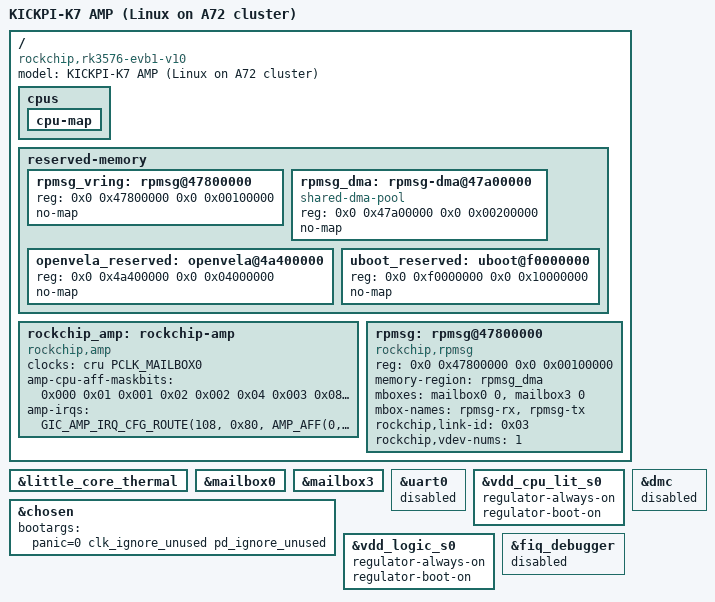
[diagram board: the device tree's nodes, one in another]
// SPDX-License-Identifier: (GPL-2.0+ OR MIT)
/*
 * KICKPI-K7 AMP：Linux 只占 A72 簇，A53 簇留给 openvela。
 *
 * 复制到 kernel-6.1/arch/arm64/boot/dts/rockchip/ 后编译。
 * 基线是 SDK 自带的 rk3576-kickpi-k7-linux.dts（K7 在 SDK 里是有板级
 * 支持的，不用拿 EVB 凑）。
 *
 * Copyright (c) 2026 contest2026_423_nanshannan
 */

/dts-v1/;

#include "rk3576.dtsi"
#include "rk3576-kickpi-k7.dtsi"
#include "rk3576-linux.dtsi"
#include <dt-bindings/soc/rockchip-amp.h>

/* MPIDR 的两段：低 8 位是簇内核号，高 8 位是簇号 */
#define AMP_AFF(core, cluster)	(((core) << 0) | ((cluster) << 8))

/ {
	model = "KICKPI-K7 AMP (Linux on A72 cluster)";
	compatible = "rockchip,rk3576-evb1-v10", "rockchip,rk3576";

	/*
	 * ★ A53 的四个 cpu 节点必须**删掉**，不能只标 status = "disabled"。
	 *
	 * 这版 vendor 内核枚举 CPU 时不看 status，标 disabled 它照样会去
	 * PSCI CPU_ON 那四个核 —— 而那四个核此刻正在跑 openvela。结果是
	 * 两个 OS 同时以为自己拥有同一颗核。
	 *
	 * 这一条来自同届 contest2026_062_PharosTech 的板测结论
	 * （其 tools/amp/TOPOLOGY.md），不是我们自己试出来的。
	 *
	 * 删 cpu 节点会留下悬空引用，所以 cpu-map 和 PMU 的 interrupt-affinity
	 * 也要一起改。
	 */

	cpus {
		/delete-node/ cpu@0;
		/delete-node/ cpu@1;
		/delete-node/ cpu@2;
		/delete-node/ cpu@3;

		cpu-map {
			/delete-node/ cluster0;
		};
	};

	/*
	 * 删掉 cpu_l* 会留下两处悬空的 phandle 引用。dtc 会直接报错，不会让
	 * 你带着它们编过去 —— 这一点恰恰比 status = "disabled" 好：后者编得过，
	 * 错误留到运行期才炸。
	 *
	 *   pmu-a53 的 interrupt-affinity → cpu_l0..l3
	 *   little-core-thermal 的 map0   → cpu_l0（A53 簇的调频降温，
	 *                                  这个簇的频率现在归 openvela）
	 */

	/delete-node/ pmu-a53;

	/*
	 * AMP 共享内存。这三段必须和 openvela 侧对上：
	 *   chip/rk3576/include/amp.h 的 RK3576_RPTUN_*
	 *   board/kickpi-k7/configs/amp/defconfig 的 CONFIG_RK3576_RPTUN_SHM_BASE
	 *
	 * no-map：不能让 Linux 把它当普通内存用。Rockchip 的 rpmsg 驱动对
	 * vring 用 ioremap()，对缓冲池用 shared-dma-pool，两者都要求这块
	 * 内存不在内核的线性映射里。
	 */

	reserved-memory {
		#address-cells = <2>;
		#size-cells = <2>;
		ranges;

		rpmsg_vring: rpmsg@47800000 {
			reg = <0x0 0x47800000 0x0 0x00100000>;
			no-map;
		};

		rpmsg_dma: rpmsg-dma@47a00000 {
			compatible = "shared-dma-pool";
			reg = <0x0 0x47a00000 0x0 0x00200000>;
			no-map;
		};

		/*
		 * openvela 自己那一块。Linux 完全不碰，只是占位，免得内核把它
		 * 分配出去。
		 *
		 * 起点 = openvela 的 CONFIG_RAM_START，长度 = CONFIG_RAM_SIZE
		 * （64MB）。这两个数必须和 board/kickpi-k7/configs/amp/defconfig
		 * 一致：写小了 Linux 会把 openvela 的堆当成自己的内存分出去，
		 * 表现是两边随机踩对方的数据，谁先崩不一定。
		 */

		openvela_reserved: openvela@4a400000 {
			reg = <0x0 0x4a400000 0x0 0x04000000>;
			no-map;
		};

		/*
		 * ★ U-Boot 自己占的那一段，也必须保留。
		 *
		 *   AMP 里 U-Boot 在 PSCI 拉起 Linux **之后**还要继续跑几毫秒：
		 *   处理 loadables、flush_dcache_all、最后才 armv8_switch_to_el2
		 *   跳进 openvela。而它重定位后位于高位内存（本板
		 *   0x40200000 + reloc_off ≈ 0xfdc1b000，栈和 malloc 在其下方）。
		 *
		 *   Linux 的 /memory 覆盖这一段。它的页分配器一旦工作，就可能把
		 *   U-Boot 正在执行的代码或它的栈分配出去 —— 表现是 **CPU0 在
		 *   任意一行上静默死掉，而 Linux 一切正常**，看起来像"openvela
		 *   没被启动"。
		 *
		 *   这一条上板踩过：Linux 拿错 FDT 秒死的那几轮，CPU0 反而能顺利
		 *   跳进 openvela；等 Linux 真的跑起来，CPU0 就再也走不到那一步。
		 *   两个现象合在一起才指向这里。
		 *
		 *   ★ 范围不能按 relocaddr 往上算 —— 第一次就是这么错的。
		 *
		 *   日志里 `Relocation Offset: bda1b000` + TEXT_BASE 0x40200000
		 *   = 0xfdc1b000，看起来从 0xfd000000 留 48MB 就够了。实际不够：
		 *   relocaddr **下面**还有 FDT 拷贝、CONFIG_SYS_MALLOC_LEN 那个
		 *   几十 MB 的 malloc 池、bd_info，然后才是向下生长的栈。
		 *
		 *   现场证据：U-Boot 崩在 `esr 0x86000006`（取指异常）、
		 *   `ELR(PC) = 0`、`SP = 0xfb9f9b40` —— 栈在 0xfb9f9xxx，在
		 *   0xfd000000 **外面**，被 Linux 分配掉之后返回地址变成 0，
		 *   于是跳到 0。
		 *
		 *   所以从 0xf0000000 起留 256MB，把 relocaddr、malloc 池、栈、
		 *   sysmem 全包进去。板上 4GB DDR，Linux 少 256MB 毫无影响 ——
		 *   它在这套方案里只是计算域。
		 */

		uboot_reserved: uboot@f0000000 {
			reg = <0x0 0xf0000000 0x0 0x10000000>;
			no-map;
		};
	};

	/*
	 * ★ Rockchip 自带的 Linux 侧 AMP 支持。这一节是整份 DTS 里最关键的。
	 *
	 *   配上 CONFIG_ROCKCHIP_AMP=y 之后，Linux 的 gic_dist_init() 会读
	 *   下面这张 amp-irqs 表，把表里的 IRQ 路由到**另一个 OS 的核**，
	 *   而不是像默认那样全部指向自己（drivers/irqchip/irq-gic.c:525）：
	 *
	 *     for (j = 0; j < 4; j++) {
	 *             if (rockchip_amp_need_init_amp_irq(i + j))
	 *                     maskval |= rockchip_amp_get_irq_cpumask(i + j) << (j * 8);
	 *             else
	 *                     maskval |= cpumask << (j * 8);
	 *     }
	 *
	 *   没有这一节的后果（实测）：Linux 在 ~0.3s 把所有 SPI 抢回自己
	 *   那颗核，openvela 早期注册的控制台和定时器中断从此送不到本核；
	 *   它的外设日志还能靠 FIFO 轮询挤出来，但打 NuttShell 横幅要走
	 *   TX 中断，于是**只打出一个字母 "N" 就停住**。
	 *
	 *   这比在 openvela 侧按字节把 SPI 抢回来干净得多，而且**顺序竞争
	 *   整个消失** —— 不需要让引导器等对端的第一次门铃再启动 openvela。
	 *   （openvela 侧那个按字节认领的补丁保留着当兜底，防漏填。）
	 *
	 * ★ clocks = <&cru PCLK_MAILBOX0>
	 *
	 *   让 Linux 认为这个时钟**有人用**，clk_disable_unused() 就不会关它。
	 *   这是声明式的，比在 bootargs 里加 clk_ignore_unused 那个大锤精确。
	 *
	 * ★ amp-cpu-aff-maskbits：MPIDR → GIC 的 CPU 接口位
	 *
	 *   A53 簇是 GIC 接口 0..3，A72 簇是 4..7。这个对应关系没有任何
	 *   规范保证，必须显式声明（openvela 侧是从 IRQ 0..31 的 ITARGETSR
	 *   读出来的，两处应当一致）。
	 *
	 * 这一节的做法来自同届 contest2026_062_PharosTech 公开的方案；
	 * 机制本身是 Rockchip 自带的，我此前完全漏了，在 openvela 侧重新
	 * 发明了一遍。
	 */

	rockchip_amp: rockchip-amp {
		compatible = "rockchip,amp";
		clocks = <&cru PCLK_MAILBOX0>;

		amp-cpu-aff-maskbits = /bits/ 64 <
			0x000 0x01 0x001 0x02 0x002 0x04 0x003 0x08
			0x100 0x10 0x101 0x20 0x102 0x40 0x103 0x80>;

		/* openvela 拥有的中断，全部路由到 A53 簇 core0。
		 * 108 = UART0（调试口）      174 = mailbox3 BB（rpmsg 收）
		 *  77 = bustimer0 CH0（闹钟）  64 = dmac0（PL330）
		 */
		amp-irqs = /bits/ 64 <
                /* ★ 这张表必须列全 openvela 用到的**每一条** SPI。
                 *
                 *   Linux 的 gic_dist_init()/gic_dist_config() 会按这张表
                 *   设目标 CPU 和优先级，没列到的一律按"归 Linux"处理 ——
                 *   目标指向 A72 簇，openvela 那边就再也收不到。
                 *
                 *   漏一条的现象非常局部、也非常难猜：这次漏的是 GPIO0
                 *   （185），后果是**触摸完全没反应**，而 /dev/input0 存在、
                 *   驱动日志正常、LVGL 也报"触摸 可用" —— 因为中断根本
                 *   没到 CPU，驱动那一侧什么都不知道。
                 *
                 *   编号是 GIC 绝对中断号 = dtsi 里的 SPI 号 + 32，和
                 *   openvela 侧 irq_attach() 用的是同一套。
                 */

                /* 串口控制台 UART0（SPI 76） */
                GIC_AMP_IRQ_CFG_ROUTE(108, 0x80, AMP_AFF(0, 0))

                /* mailbox0 group3 BB 侧接收（SPI 142）—— AMP 的门铃 */
                GIC_AMP_IRQ_CFG_ROUTE(174, 0x80, AMP_AFF(0, 0))

                /* 系统定时器 timer5（SPI 45） */
                GIC_AMP_IRQ_CFG_ROUTE(77,  0x80, AMP_AFF(0, 0))

                /* PL330 dmac0 的两条中断线（SPI 32/33） */
                GIC_AMP_IRQ_CFG_ROUTE(64,  0x80, AMP_AFF(0, 0))
                GIC_AMP_IRQ_CFG_ROUTE(65,  0x80, AMP_AFF(0, 0))

                /* GPIO 五个 bank（SPI 153/157/161/165/169）。
                 * bank 内 32 个引脚共用一条线，触摸中断在 bank0。
                 */
                GIC_AMP_IRQ_CFG_ROUTE(185, 0x80, AMP_AFF(0, 0))
                GIC_AMP_IRQ_CFG_ROUTE(189, 0x80, AMP_AFF(0, 0))
                GIC_AMP_IRQ_CFG_ROUTE(193, 0x80, AMP_AFF(0, 0))
                GIC_AMP_IRQ_CFG_ROUTE(197, 0x80, AMP_AFF(0, 0))
                GIC_AMP_IRQ_CFG_ROUTE(201, 0x80, AMP_AFF(0, 0))

                /* GMAC1：macirq（SPI 301）与 DMA 通道线（SPI 304） */
                GIC_AMP_IRQ_CFG_ROUTE(333, 0x80, AMP_AFF(0, 0))
                GIC_AMP_IRQ_CFG_ROUTE(336, 0x80, AMP_AFF(0, 0))

                /* CIF（SPI 318）—— 摄像头 */
                GIC_AMP_IRQ_CFG_ROUTE(350, 0x80, AMP_AFF(0, 0))>;

		status = "okay";
	};

	/*
	 * Rockchip 的 rpmsg-over-mailbox。Linux 站 master。
	 *
	 * mboxes 的两个名字容易和方向搞混：
	 *   "rpmsg-rx" = Linux 收，对应 openvela 的发送 group（0）
	 *   "rpmsg-tx" = Linux 发，对应 openvela 的接收 group（3）
	 *
	 * reg 是 vring 区：驱动按 vdev-nums 从这里依次切两段 0x8000。
	 */

	rpmsg: rpmsg@47800000 {
		compatible = "rockchip,rpmsg";
		reg = <0x0 0x47800000 0x0 0x00100000>;
		memory-region = <&rpmsg_dma>;
		mboxes = <&mailbox0 0>, <&mailbox3 0>;
		mbox-names = "rpmsg-rx", "rpmsg-tx";
		rockchip,link-id = <0x03>;
		rockchip,vdev-nums = <1>;
		status = "okay";
	};
};

&little_core_thermal {
	/delete-node/ cooling-maps;
};

&mailbox0 {
	status = "okay";
};

&mailbox3 {
	status = "okay";
};

/*
 * UART0 是 openvela 的调试口（CH340 那一路）。两个 OS 同时初始化同一个
 * 16550 的表现是字符互相插队、波特率被对方改掉，而且谁都不报错。
 *
 * 所以 Linux 这边彻底关掉它。Linux 在这一版**没有控制台** —— 它活着的
 * 证据是 openvela 那边 `ampctl status` 的"握手完成"变成"是"：那个信号
 * 只有在 Linux 跑到 rockchip_rpmsg 的 probe、建好两个 virtqueue、填好
 * 接收缓冲之后才会发出来，是一个相当靠后、相当可信的存活判据。
 *
 * 真要看 Linux 的日志，40pin 上还有 UART5_M0（21/23 脚）等几路可以接
 * 第二个 USB-TTL；那属于调试时的可选项，不是这一版的前提。
 */

/*
 * ★ /chosen/bootargs 必须覆盖掉，不能只在 U-Boot 里 setenv bootargs。
 *
 *   rk3576-linux.dtsi 里带着厂商的那一串：
 *
 *     earlycon=uart8250,mmio32,0x2ad40000 console=ttyFIQ0
 *     root=PARTUUID=614e0000-0000 rw rootwait ...
 *
 *   而 U-Boot 的 bootargs_add_dtb_dtbo()（arch/arm/mach-rockchip/board.c）
 *   会把内核 DTB 里的 /chosen/bootargs **追加**到 env 的 bootargs 上。
 *   所以在 U-Boot 提示符下 `setenv bootargs 'panic=0'` 之后，内核实际拿到
 *   的仍然是 `panic=0 ... earlycon=uart8250,mmio32,0x2ad40000 ...`。
 *
 *   那个 earlycon 指向 **UART0**，而 UART0 归 openvela。两个 OS 同时往
 *   同一个 16550 写，表现是字符逐个交错、控制台彻底不可读，而且谁都不
 *   报错。这一条上板踩过：双 OS 跑起来后 openvela 的输出整段消失，
 *   看起来像 openvela 没起来，实际是它的字被 Linux 的 earlycon 冲掉了。
 *
 *   这一版 Linux **不需要控制台**：它是纯计算域，存活判据是 openvela 那边
 *   ampctl status 的"握手完成"（见 amp/OWNERSHIP.md）。真要看 Linux 日志，
 *   用 rk3576-kickpi-k7-amp-dbg.dts 那个变体，它把 UART0 让给 Linux，
 *   但**只能在不启 openvela 的隔离实验里用**。
 *
 *   panic=0：Linux 没有 rootfs，挂载根失败必然 panic。panic=0 让它停住
 *   而不是重启 —— 重启走的是 PSCI SYSTEM_RESET，**会把整片 SoC 连
 *   openvela 一起复位**。AMP 下一侧的"正常错误处理"就是另一侧的灾难。
 */

&chosen {
	/*
	 * ★ clk_ignore_unused / pd_ignore_unused 在 AMP 下是**必需**的，
	 *   不是优化。
	 *
	 *   Linux 在 late_initcall 会跑 clk_disable_unused() 和电源域的
	 *   同一套逻辑：把**没有 Linux 消费者**的时钟和电源域全部关掉。
	 *   而 openvela 用的 UART0、SAI、VOP2、I2C、GMAC、CIF……在 Linux
	 *   眼里全都"没人用"（它们的节点要么被删了、要么 disabled）。
	 *
	 *   于是 Linux 会把 openvela 脚下的时钟一个个抽掉。表现是
	 *   **openvela 在初始化中途任意一行静默停住**（本次是 SAI 之后），
	 *   而 Linux 一切正常 —— 看起来像 openvela 自己的 bug。
	 *
	 *   判据很硬：同一份 openvela、同一个配置，FIT 里不带 Linux 时
	 *   一路跑到 NSH 并稳住；带上 Linux 就死在半路。
	 *
	 *   panic=0：Linux 没有 rootfs，挂根必然 panic。panic=0 让它停住而
	 *   不是重启 —— 重启走 PSCI SYSTEM_RESET，会把整片 SoC 连 openvela
	 *   一起复位。一侧的"正常错误处理"就是另一侧的灾难。
	 */
	/*
	 * clk_ignore_unused / pd_ignore_unused 现在是**兜底**，不是主手段 ——
	 * 主手段是上面 rockchip-amp 节点里声明 openvela 用到的资源。
	 * 留着它们的理由：那张声明表难免漏，而漏掉一项的代价是 openvela
	 * 在某一行静默死掉，排查成本远高于多留几个时钟。
	 */
	bootargs = "panic=0 clk_ignore_unused pd_ignore_unused";
};

&uart0 {
	status = "disabled";
};

/*
 * ★ 稳压器必须钉住。
 *
 *   vdd_cpu_lit_s0 是 **A53 簇的供电**，vdd_logic_s0 是逻辑域的供电。
 *   Linux 的 regulator 框架会在初始化末尾把"没有消费者"的稳压器关掉 ——
 *   而在 AMP 下 A53 簇的消费者（那四个 cpu 节点）已经被我们删掉了，
 *   于是在 Linux 眼里它没人用。
 *
 *   后果不是报错。实测是 openvela 访问某个外设时拿到
 *   **synchronous external abort**（ESR 0x96000010，FAR 0x27d80000 = DSI）
 *   —— 总线拒绝，因为那一侧的供电被降了。看起来像"那个驱动有问题"。
 *
 *   regulator-state-mem 也要删：那是休眠时的目标电压，AMP 下不该有人
 *   替另一个 OS 决定休眠电压。
 */

&vdd_cpu_lit_s0 {
	/delete-property/ regulator-init-microvolt;
	regulator-always-on;
	regulator-boot-on;
	/delete-node/ regulator-state-mem;
};

&vdd_logic_s0 {
	/delete-property/ regulator-init-microvolt;
	regulator-always-on;
	regulator-boot-on;
	/delete-node/ regulator-state-mem;
};

/*
 * ★ DDR 变频必须关。
 *
 *   dmc 的 devfreq 会在运行时改 DDR 频率。openvela 的时序参数（串口
 *   分频、SAI 的 MCLK、定时器）都建立在当前频率上，另一个 OS 在它脚下
 *   改 DDR 频率是灾难性的，而且没有任何通知机制。
 */

&dmc {
	status = "disabled";
};

&fiq_debugger {
	status = "disabled";
};
